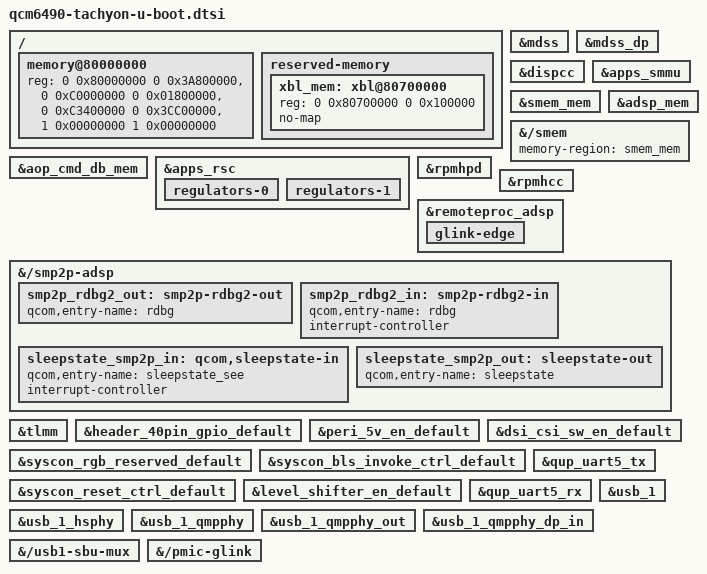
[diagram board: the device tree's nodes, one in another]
// SPDX-License-Identifier: BSD-3-Clause
/*
 * Copyright (c) 2024 Linaro Ltd.
 */

/delete-node/ &xbl_mem;

/ {
	/* When running as the primary bootloader there is no prior
	 * stage to populate the memory layout for us. We *should*
	 * have two nodes here, but ABL does NOT like that.
	 * sooo we're stuck with this.
	 */
	memory@80000000 {
		device_type = "memory";
		reg = <0 0x80000000 0 0x3A800000>,
		      <0 0xC0000000 0 0x01800000>,
		      <0 0xC3400000 0 0x3CC00000>,
		      <1 0x00000000 1 0x00000000>;
	};

	reserved-memory {
		#address-cells = <2>;
		#size-cells = <2>;
		ranges;

		/* XBL (eXtensible Boot Loader) region */
		xbl_mem: xbl@80700000 {
			reg = <0 0x80700000 0 0x100000>;
			no-map;
		};
	};

	// RAM Entry 0 : Base 0x0080000000  Size 0x003A800000
	// RAM Entry 1 : Base 0x00C0000000  Size 0x0001800000
	// RAM Entry 2 : Base 0x00C3400000  Size 0x003CC00000
	// RAM Entry 3 : Base 0x0100000000  Size 0x0100000000
};

&mdss {
	bootph-all;
};

&mdss_dp {
	bootph-all;
};

&dispcc {
	bootph-all;
};

&apps_smmu {
	bootph-all;
};

&{/reserved-memory} {
	bootph-all;
};

&smem_mem {
	bootph-all;
};

&adsp_mem {
	bootph-all;
};

&{/smem} {
	memory-region = <&smem_mem>;
	bootph-all;
};

&aop_cmd_db_mem {
	bootph-all;
};

&apps_rsc {
	bootph-all;

	regulators-0 {
		bootph-all;
	};

	regulators-1 {
		bootph-all;
	};
};

&rpmhpd {
	bootph-all;
};

&rpmhcc {
	bootph-all;
};

&remoteproc_adsp {
	status = "okay";
	bootph-all;

	glink-edge {
		bootph-all;
	};
};

/* Linux QCM6490 addon SMP2P entries needed before ADSP release. */
&{/smp2p-adsp} {
	smp2p_rdbg2_out: smp2p-rdbg2-out {
		qcom,entry-name = "rdbg";
		#qcom,smem-state-cells = <1>;
	};

	smp2p_rdbg2_in: smp2p-rdbg2-in {
		qcom,entry-name = "rdbg";
		interrupt-controller;
		#interrupt-cells = <2>;
	};

	sleepstate_smp2p_in: qcom,sleepstate-in {
		qcom,entry-name = "sleepstate_see";
		interrupt-controller;
		#interrupt-cells = <2>;
	};

	sleepstate_smp2p_out: sleepstate-out {
		qcom,entry-name = "sleepstate";
		#qcom,smem-state-cells = <1>;
	};
};

&tlmm {
	bootph-all;
};

/*
 * &tlmm carries its own "default" pinctrl hog (pinctrl-0 in qcm6490-tachyon.dts:
 * header_40pin_gpio, peri_5v_en, dsi_csi_sw_en, syscon_rgb_reserved,
 * syscon_bls_invoke_ctrl, syscon_reset_ctrl, level_shifter_en). Because &tlmm is
 * bootph-all it binds and probes in the pre-reloc DM pass, and DM auto-applies
 * the controller's own "default" state there (drivers/core/device.c). As with the
 * uart5 pins below, pinconfig_post_bind() gates each state child on a node-level
 * bootph check that is NOT inherited from &tlmm, so without bootph-all on these
 * nodes the PINCONFIG devices don't exist yet in the pre-reloc pass and
 * pinctrl_select_state() warns once per phandle:
 *   pinctrl_select_state_full: uclass_get_device_by_phandle_id: err=-19
 * Mark them so they bind pre-relocation and the hog applies cleanly.
 */
&header_40pin_gpio_default {
	bootph-all;
};

&peri_5v_en_default {
	bootph-all;
};

&dsi_csi_sw_en_default {
	bootph-all;
};

&syscon_rgb_reserved_default {
	bootph-all;
};

&syscon_bls_invoke_ctrl_default {
	bootph-all;
};

&syscon_reset_ctrl_default {
	bootph-all;
};

&level_shifter_en_default {
	bootph-all;
};

/*
 * The debug UART (uart5, serial@994000) is the pre-relocation console: its
 * driver carries DM_FLAG_PRE_RELOC, so it binds and probes in the pre-reloc
 * DM pass and DM auto-applies its "default" pinctrl state there. The pinmux
 * state nodes are bound separately by pinconfig_post_bind(), which gates each
 * child on a node-level bootph check that is NOT inherited from &tlmm. Without
 * bootph-all here the PINCONFIG devices don't exist yet in the pre-reloc pass,
 * so pinctrl_select_state() warns:
 *   pinctrl_select_state_full: uclass_get_device_by_phandle_id: err=-19
 * once per phandle (tx + rx). Mark them so they bind pre-relocation too.
 */
&qup_uart5_tx {
	bootph-all;
};

&qup_uart5_rx {
	bootph-all;
};

/* Keep USB-C/DP related nodes available to U-Boot. Do not change Linux semantics. */
&usb_1 {
	bootph-all;
};


&usb_1_hsphy {
	bootph-all;
};

&usb_1_qmpphy {
	bootph-all;
};

&usb_1_qmpphy_out {
	bootph-all;
};

&usb_1_qmpphy_dp_in {
	bootph-all;
};

&{/usb1-sbu-mux} {
	bootph-all;
};

/* Bind the PMIC-GLINK core (UCLASS_PMIC_GLINK) early so the Type-C/DP path
 * can reach the GLINK transport in whatever phase it probes. */
&{/pmic-glink} {
	bootph-all;
};
